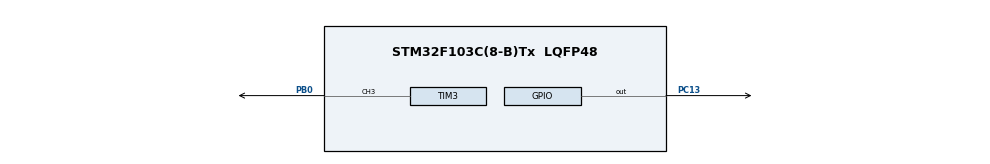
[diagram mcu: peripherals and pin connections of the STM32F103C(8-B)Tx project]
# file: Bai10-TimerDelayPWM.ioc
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Mcu.Family=STM32F1
Mcu.Name=STM32F103C(8-B)Tx
Mcu.Package=LQFP48
NVIC.PriorityGroup=NVIC_PRIORITYGROUP_4
PA13.Mode=Serial_Wire
PA13.Signal=SYS_JTMS-SWDIO
PA14.Mode=Serial_Wire
PA14.Signal=SYS_JTCK-SWCLK
PB0.Signal=S_TIM3_CH3
PC13-TAMPER-RTC.Signal=GPIO_Output
PD0-OSC_IN.Mode=HSE-External-Oscillator
PD0-OSC_IN.Signal=RCC_OSC_IN
PD1-OSC_OUT.Mode=HSE-External-Oscillator
PD1-OSC_OUT.Signal=RCC_OSC_OUT
ProjectManager.HeapSize=0x200
ProjectManager.StackSize=0x400
ProjectManager.TargetToolchain=MDK-ARM V5
RCC.APB1Freq_Value=8000000
RCC.APB2Freq_Value=8000000
RCC.SYSCLKSource=RCC_SYSCLKSOURCE_HSE
SH.S_TIM3_CH3.0=TIM3_CH3,PWM Generation3 CH3
TIM1.Channel-PWM\ Generation1\ CH1=TIM_CHANNEL_1
TIM1.Prescaler=8-1
TIM3.Channel-PWM\ Generation3\ CH3=TIM_CHANNEL_3
TIM3.Period=100-1
TIM3.Prescaler=8-1
VP_TIM1_VS_ClockSourceINT.Mode=Internal
VP_TIM3_VS_ClockSourceINT.Mode=Internal
board=Bai10-TimerDelayPWM

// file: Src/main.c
/**
  ******************************************************************************
  * File Name          : main.c
  * Description        : Main program body
  ******************************************************************************
  ** This notice applies to any and all portions of this file
  * that are not between comment pairs USER CODE BEGIN and
  * USER CODE END. Other portions of this file, whether
  * inserted by the user or by software development tools
  * are owned by their respective copyright owners.
  *
  * COPYRIGHT(c) 2017 STMicroelectronics
  *
  * Redistribution and use in source and binary forms, with or without modification,
  * are permitted provided that the following conditions are met:
  *   1. Redistributions of source code must retain the above copyright notice,
  *      this list of conditions and the following disclaimer.
  *   2. Redistributions in binary form must reproduce the above copyright notice,
  *      this list of conditions and the following disclaimer in the documentation
  *      and/or other materials provided with the distribution.
  *   3. Neither the name of STMicroelectronics nor the names of its contributors
  *      may be used to endorse or promote products derived from this software
  *      without specific prior written permission.
  *
  * THIS SOFTWARE IS PROVIDED BY THE COPYRIGHT HOLDERS AND CONTRIBUTORS "AS IS"
  * AND ANY EXPRESS OR IMPLIED WARRANTIES, INCLUDING, BUT NOT LIMITED TO, THE
  * IMPLIED WARRANTIES OF MERCHANTABILITY AND FITNESS FOR A PARTICULAR PURPOSE ARE
  * DISCLAIMED. IN NO EVENT SHALL THE COPYRIGHT HOLDER OR CONTRIBUTORS BE LIABLE
  * FOR ANY DIRECT, INDIRECT, INCIDENTAL, SPECIAL, EXEMPLARY, OR CONSEQUENTIAL
  * DAMAGES (INCLUDING, BUT NOT LIMITED TO, PROCUREMENT OF SUBSTITUTE GOODS OR
  * SERVICES; LOSS OF USE, DATA, OR PROFITS; OR BUSINESS INTERRUPTION) HOWEVER
  * CAUSED AND ON ANY THEORY OF LIABILITY, WHETHER IN CONTRACT, STRICT LIABILITY,
  * OR TORT (INCLUDING NEGLIGENCE OR OTHERWISE) ARISING IN ANY WAY OUT OF THE USE
  * OF THIS SOFTWARE, EVEN IF ADVISED OF THE POSSIBILITY OF SUCH DAMAGE.
  *
  ******************************************************************************
  */
#include "main.h"
#include "stm32f1xx_hal.h"

/* USER CODE BEGIN Includes */

//hung
#include "textLCD.h"

/* USER CODE END Includes */

TIM_HandleTypeDef htim1;
TIM_HandleTypeDef htim3;

/* USER CODE BEGIN PV */
/* Private variables ---------------------------------------------------------*/

//Hung
volatile uint32_t counter=0;
char lcdBuff[20];

/* USER CODE END PV */

void SystemClock_Config(void);
static void MX_GPIO_Init(void);
static void MX_TIM1_Init(void);
static void MX_TIM3_Init(void);

void HAL_TIM_MspPostInit(TIM_HandleTypeDef *htim);

/* USER CODE BEGIN PFP */
/* Private function prototypes -----------------------------------------------*/

/* USER CODE END PFP */

/* USER CODE BEGIN 0 */

void delay_us(uint32_t us)
{
	uint32_t time;

	HAL_TIM_Base_Start(&htim1);

		while(1)
			{
				time = __HAL_TIM_GetCounter(&htim1);
				if ((us-time) == 0) break;
		};

		HAL_TIM_Base_Stop(&htim1);
}

/* USER CODE END 0 */

int main(void)
{

  /* USER CODE BEGIN 1 */

	//HUng
	unsigned int pwm;

  /* USER CODE END 1 */

  /* MCU Configuration----------------------------------------------------------*/

  /* Reset of all peripherals, Initializes the Flash interface and the Systick. */
  HAL_Init();

  /* Configure the system clock */
  SystemClock_Config();

  /* Initialize all configured peripherals */
  MX_GPIO_Init();
  MX_TIM1_Init();
  MX_TIM3_Init();

  /* USER CODE BEGIN 2 */

	//Hung
	HAL_TIM_PWM_Start(&htim3, TIM_CHANNEL_3);
	HAL_TIM_Base_Init(&htim1);

	lcd_init();

  /* USER CODE END 2 */

  /* Infinite loop */
  while (1)
  {

		//Hung
		for(pwm = 0; pwm < 200; pwm++){
			__HAL_TIM_SetCompare(&htim3, TIM_CHANNEL_3, pwm);
			HAL_Delay(50);
		}
		HAL_Delay(100);

		for(pwm = 200; pwm > 0; pwm--){
			__HAL_TIM_SetCompare(&htim3, TIM_CHANNEL_3, pwm);
			HAL_Delay(50);
		}
//
		counter = __HAL_TIM_GetCounter(&htim1);

		sprintf(&lcdBuff[0], "Counter: %0.2d", counter);
		lcd_gotoxy(0,0);
		lcd_puts(&lcdBuff[0]);

		HAL_GPIO_TogglePin(GPIOC, GPIO_PIN_13);
		HAL_Delay(1000);

  }

}

/** System Clock Configuration
*/
void SystemClock_Config(void)
{

  RCC_OscInitTypeDef RCC_OscInitStruct;
  RCC_ClkInitTypeDef RCC_ClkInitStruct;

    /**Initializes the CPU, AHB and APB busses clocks
    */
  RCC_OscInitStruct.OscillatorType = RCC_OSCILLATORTYPE_HSE;
  RCC_OscInitStruct.HSEState = RCC_HSE_ON;
  RCC_OscInitStruct.PLL.PLLState = RCC_PLL_NONE;
  if (HAL_RCC_OscConfig(&RCC_OscInitStruct) != HAL_OK)
  {
    _Error_Handler(__FILE__, __LINE__);
  }

    /**Initializes the CPU, AHB and APB busses clocks
    */
  RCC_ClkInitStruct.ClockType = RCC_CLOCKTYPE_HCLK|RCC_CLOCKTYPE_SYSCLK
                              |RCC_CLOCKTYPE_PCLK1|RCC_CLOCKTYPE_PCLK2;
  RCC_ClkInitStruct.SYSCLKSource = RCC_SYSCLKSOURCE_HSE;
  RCC_ClkInitStruct.AHBCLKDivider = RCC_SYSCLK_DIV1;
  RCC_ClkInitStruct.APB1CLKDivider = RCC_HCLK_DIV1;
  RCC_ClkInitStruct.APB2CLKDivider = RCC_HCLK_DIV1;

  if (HAL_RCC_ClockConfig(&RCC_ClkInitStruct, FLASH_LATENCY_0) != HAL_OK)
  {
    _Error_Handler(__FILE__, __LINE__);
  }

    /**Configure the Systick interrupt time
    */
  HAL_SYSTICK_Config(HAL_RCC_GetHCLKFreq()/1000);

    /**Configure the Systick
    */
  HAL_SYSTICK_CLKSourceConfig(SYSTICK_CLKSOURCE_HCLK);

  /* SysTick_IRQn interrupt configuration */
  HAL_NVIC_SetPriority(SysTick_IRQn, 0, 0);
}

/* TIM1 init function */
static void MX_TIM1_Init(void)
{

  TIM_ClockConfigTypeDef sClockSourceConfig;
  TIM_MasterConfigTypeDef sMasterConfig;

  htim1.Instance = TIM1;
  htim1.Init.Prescaler = 8-1;
  htim1.Init.CounterMode = TIM_COUNTERMODE_UP;
  htim1.Init.Period = 100-1;
  htim1.Init.ClockDivision = TIM_CLOCKDIVISION_DIV1;
  htim1.Init.RepetitionCounter = 0;
  if (HAL_TIM_Base_Init(&htim1) != HAL_OK)
  {
    _Error_Handler(__FILE__, __LINE__);
  }

  sClockSourceConfig.ClockSource = TIM_CLOCKSOURCE_INTERNAL;
  if (HAL_TIM_ConfigClockSource(&htim1, &sClockSourceConfig) != HAL_OK)
  {
    _Error_Handler(__FILE__, __LINE__);
  }

  sMasterConfig.MasterOutputTrigger = TIM_TRGO_RESET;
  sMasterConfig.MasterSlaveMode = TIM_MASTERSLAVEMODE_DISABLE;
  if (HAL_TIMEx_MasterConfigSynchronization(&htim1, &sMasterConfig) != HAL_OK)
  {
    _Error_Handler(__FILE__, __LINE__);
  }

}

/* TIM3 init function */
static void MX_TIM3_Init(void)
{

  TIM_ClockConfigTypeDef sClockSourceConfig;
  TIM_MasterConfigTypeDef sMasterConfig;
  TIM_OC_InitTypeDef sConfigOC;

  htim3.Instance = TIM3;
  htim3.Init.Prescaler = 8-1;
  htim3.Init.CounterMode = TIM_COUNTERMODE_UP;
  htim3.Init.Period = 100-1;
  htim3.Init.ClockDivision = TIM_CLOCKDIVISION_DIV1;
  if (HAL_TIM_Base_Init(&htim3) != HAL_OK)
  {
    _Error_Handler(__FILE__, __LINE__);
  }

  sClockSourceConfig.ClockSource = TIM_CLOCKSOURCE_INTERNAL;
  if (HAL_TIM_ConfigClockSource(&htim3, &sClockSourceConfig) != HAL_OK)
  {
    _Error_Handler(__FILE__, __LINE__);
  }

  if (HAL_TIM_PWM_Init(&htim3) != HAL_OK)
  {
    _Error_Handler(__FILE__, __LINE__);
  }

  sMasterConfig.MasterOutputTrigger = TIM_TRGO_RESET;
  sMasterConfig.MasterSlaveMode = TIM_MASTERSLAVEMODE_DISABLE;
  if (HAL_TIMEx_MasterConfigSynchronization(&htim3, &sMasterConfig) != HAL_OK)
  {
    _Error_Handler(__FILE__, __LINE__);
  }

  sConfigOC.OCMode = TIM_OCMODE_PWM1;
  sConfigOC.Pulse = 0;
  sConfigOC.OCPolarity = TIM_OCPOLARITY_HIGH;
  sConfigOC.OCFastMode = TIM_OCFAST_DISABLE;
  if (HAL_TIM_PWM_ConfigChannel(&htim3, &sConfigOC, TIM_CHANNEL_3) != HAL_OK)
  {
    _Error_Handler(__FILE__, __LINE__);
  }

  HAL_TIM_MspPostInit(&htim3);

}

/** Configure pins as
        * Analog
        * Input
        * Output
        * EVENT_OUT
        * EXTI
*/
static void MX_GPIO_Init(void)
{

  GPIO_InitTypeDef GPIO_InitStruct;

  /* GPIO Ports Clock Enable */
  __HAL_RCC_GPIOC_CLK_ENABLE();
  __HAL_RCC_GPIOD_CLK_ENABLE();
  __HAL_RCC_GPIOB_CLK_ENABLE();
  __HAL_RCC_GPIOA_CLK_ENABLE();

  /*Configure GPIO pin Output Level */
  HAL_GPIO_WritePin(GPIOC, GPIO_PIN_13, GPIO_PIN_RESET);

  /*Configure GPIO pin : PC13 */
  GPIO_InitStruct.Pin = GPIO_PIN_13;
  GPIO_InitStruct.Mode = GPIO_MODE_OUTPUT_PP;
  GPIO_InitStruct.Speed = GPIO_SPEED_FREQ_LOW;
  HAL_GPIO_Init(GPIOC, &GPIO_InitStruct);

}

void _Error_Handler(char * file, int line)
{
  while(1)
  {
  }
}

/************************ (C) COPYRIGHT STMicroelectronics *****END OF FILE****/
